# EVENT register map
Vendor: Texas Instruments
Registers are 32-bit, read-only, reset 0x0 unless marked. A register's access mark holds for its fields unless they carry their own. Offsets are as the file gives them; [hi:lo] are bit positions; {n}, {i} and the like mark numbered series; 'fields as' and 'values as' point back to an identical list.

## EVENT — Event Fabric Component Definition
0x00 CPUIRQSEL0 reset 0x4 — Output Selection for CPU Interrupt 0
  [6:0] EV — Read only selection value
    4=AON_GPIO_EDGE (Edge detect event from IOC. Configureded by the IOC:IOCFGn.EDGE_IRQ_EN and IOC:IOCFGn.EDGE_DET settings)
0x04 CPUIRQSEL1 reset 0x9 — Output Selection for CPU Interrupt 1
  [6:0] EV — Read only selection value
    9=I2C_IRQ (Interrupt event from I2C)
0x08 CPUIRQSEL2 reset 0x1E — Output Selection for CPU Interrupt 2
  [6:0] EV — Read only selection value
    30=RFC_CPE_1 (Combined Interrupt for CPE Generated events. Corresponding flags are here RFC_DBELL:RFCPEIFG. Only interrupts selected with CPE1 in RFC_DBELL:RFCPEIFG can trigger a RFC_CPE_1 event)
0x0C CPUIRQSEL3 reset 0x38 — Output Selection for CPU Interrupt 3
0x10 CPUIRQSEL4 reset 0x7 — Output Selection for CPU Interrupt 4
  [6:0] EV — Read only selection value
    7=AON_RTC_COMB (Event from AON_RTC, controlled by the AON_RTC:CTL.COMB_EV_MASK setting)
0x14 CPUIRQSEL5 reset 0x24 — Output Selection for CPU Interrupt 5
  [6:0] EV — Read only selection value
    36=UART0_COMB (UART0 combined interrupt, interrupt flags are found here UART0:MIS)
0x18 CPUIRQSEL6 reset 0x1C — Output Selection for CPU Interrupt 6
  [6:0] EV — Read only selection value
    28=AUX_SWEV0 (AUX software event 0, triggered by AUX_EVCTL:SWEVSET.SWEV0, also available as AUX_EVENT0 AON wake up event. MCU domain wakeup control AON_EVENT:MCUWUSEL AUX domain wakeup control AON_EVENT:AUXWUSEL)
0x1C CPUIRQSEL7 reset 0x22 — Output Selection for CPU Interrupt 7
  [6:0] EV — Read only selection value
    34=SSI0_COMB (SSI0 combined interrupt, interrupt flags are found here SSI0:MIS)
0x20 CPUIRQSEL8 reset 0x23 — Output Selection for CPU Interrupt 8
  [6:0] EV — Read only selection value
    35=SSI1_COMB (SSI1 combined interrupt, interrupt flags are found here SSI1:MIS)
0x24 CPUIRQSEL9 reset 0x1B — Output Selection for CPU Interrupt 9
  [6:0] EV — Read only selection value
    27=RFC_CPE_0 (Combined Interrupt for CPE Generated events. Corresponding flags are here RFC_DBELL:RFCPEIFG. Only interrupts selected with CPE0 in RFC_DBELL:RFCPEIFG can trigger a RFC_CPE_0 event)
0x28 CPUIRQSEL10 reset 0x1A — Output Selection for CPU Interrupt 10
  [6:0] EV — Read only selection value
    26=RFC_HW_COMB (Combined RFC hardware interrupt, corresponding flag is here RFC_DBELL:RFHWIFG)
0x2C CPUIRQSEL11 reset 0x19 — Output Selection for CPU Interrupt 11
  [6:0] EV — Read only selection value
    25=RFC_CMD_ACK (RFC Doorbell Command Acknowledgement Interrupt, equvialent to RFC_DBELL:RFACKIFG.ACKFLAG)
0x30 CPUIRQSEL12 reset 0x8 — Output Selection for CPU Interrupt 12
  [6:0] EV — Read only selection value
    8=I2S_IRQ (Interrupt event from I2S)
0x34 CPUIRQSEL13 reset 0x1D — Output Selection for CPU Interrupt 13
  [6:0] EV — Read only selection value
    29=AUX_SWEV1 (AUX software event 1, triggered by AUX_EVCTL:SWEVSET.SWEV1, also available as AUX_EVENT2 AON wake up event. MCU domain wakeup control AON_EVENT:MCUWUSEL AUX domain wakeup control AON_EVENT:AUXWUSEL)
0x38 CPUIRQSEL14 reset 0x18 — Output Selection for CPU Interrupt 14
  [6:0] EV — Read only selection value
    24=WDT_IRQ (Watchdog interrupt event, controlled by WDT:CTL.INTEN)
0x3C CPUIRQSEL15 reset 0x10 — Output Selection for CPU Interrupt 15
  [6:0] EV — Read only selection value
    16=GPT0A (GPT0A interrupt event, controlled by GPT0:TAMR)
0x40 CPUIRQSEL16 reset 0x11 — Output Selection for CPU Interrupt 16
  [6:0] EV — Read only selection value
    17=GPT0B (GPT0B interrupt event, controlled by GPT0:TBMR)
0x44 CPUIRQSEL17 reset 0x12 — Output Selection for CPU Interrupt 17
  [6:0] EV — Read only selection value
    18=GPT1A (GPT1A interrupt event, controlled by GPT1:TAMR)
0x48 CPUIRQSEL18 reset 0x13 — Output Selection for CPU Interrupt 18
  [6:0] EV — Read only selection value
    19=GPT1B (GPT1B interrupt event, controlled by GPT1:TBMR)
0x4C CPUIRQSEL19 reset 0xC — Output Selection for CPU Interrupt 19
  [6:0] EV — Read only selection value
    12=GPT2A (GPT2A interrupt event, controlled by GPT2:TAMR)
0x50 CPUIRQSEL20 reset 0xD — Output Selection for CPU Interrupt 20
  [6:0] EV — Read only selection value
    13=GPT2B (GPT2B interrupt event, controlled by GPT2:TBMR)
0x54 CPUIRQSEL21 reset 0xE — Output Selection for CPU Interrupt 21
  [6:0] EV — Read only selection value
    14=GPT3A (GPT3A interrupt event, controlled by GPT3:TAMR)
0x58 CPUIRQSEL22 reset 0xF — Output Selection for CPU Interrupt 22
  [6:0] EV — Read only selection value
    15=GPT3B (GPT3B interrupt event, controlled by GPT3:TBMR)
0x5C CPUIRQSEL23 reset 0x5D — Output Selection for CPU Interrupt 23
  [6:0] EV — Read only selection value
    93=CRYPTO_RESULT_AVAIL_IRQ (CRYPTO result available interupt event, the corresponding flag is found here CRYPTO:IRQSTAT.RESULT_AVAIL. Controlled by CRYPTO:IRQSTAT.RESULT_AVAIL)
0x60 CPUIRQSEL24 reset 0x27 — Output Selection for CPU Interrupt 24
  [6:0] EV — Read only selection value
    39=DMA_DONE_COMB (Combined DMA done, corresponding flags are here UDMA0:REQDONE)
0x64 CPUIRQSEL25 reset 0x26 — Output Selection for CPU Interrupt 25
  [6:0] EV — Read only selection value
    38=DMA_ERR (DMA bus error, corresponds to UDMA0:ERROR.STATUS)
0x68 CPUIRQSEL26 reset 0x15 — Output Selection for CPU Interrupt 26
  [6:0] EV — Read only selection value
    21=FLASH (FLASH controller error event, the status flags are FLASH:FEDACSTAT.FSM_DONE and FLASH:FEDACSTAT.RVF_INT)
0x6C CPUIRQSEL27 reset 0x64 — Output Selection for CPU Interrupt 27
  [6:0] EV — Read only selection value
    100=SWEV0 (Software event 0, triggered by SWEV.SWEV0)
0x70 CPUIRQSEL28 reset 0xB — Output Selection for CPU Interrupt 28
  [6:0] EV — Read only selection value
    11=AUX_COMB (AUX combined event, the corresponding flag register is here AUX_EVCTL:EVTOMCUFLAGS)
0x74 CPUIRQSEL29 reset 0x1 — Output Selection for CPU Interrupt 29
  [6:0] EV — Read only selection value
    1=AON_PROG0 (AON programmable event 0. Event selected by AON_EVENT MCU event selector, AON_EVENT:EVTOMCUSEL.AON_PROG0_EV)
0x78 CPUIRQSEL30 access per field — Output Selection for CPU Interrupt 30
  [6:0] EV rw — Read/write selection value Writing any other value than values defined by a ENUM may result in undefined behavior.
    121=ALWAYS_ACTIVE (Always asserted); 119=AON_RTC_UPD (RTC periodic event controlled by AON_RTC:CTL.RTC_UPD_EN); 114=AUX_OBSMUX0 (Loopback of OBSMUX0 through AUX, corresponds to AUX_EVCTL:EVTOMCUFLAGS.OBSMUX0); 113=AUX_ADC_FIFO_ALMOST_FULL (AUX ADC FIFO watermark event, corresponds to AUX_EVCTL:EVTOMCUFLAGS.ADC_FIFO_ALMOST_FULL); 112=AUX_ADC_DONE (AUX ADC done, corresponds to AUX_EVCTL:EVTOMCUFLAGS.ADC_DONE); 111=AUX_SMPH_AUTOTAKE_DONE (Autotake event from AUX semaphore, configured by AUX_SMPH:AUTOTAKE); 110=AUX_TIMER1_EV (AUX timer 1 event, corresponds to AUX_EVCTL:EVTOMCUFLAGS.TIMER1_EV); 109=AUX_TIMER0_EV (AUX timer 0 event, corresponds to AUX_EVCTL:EVTOMCUFLAGS.TIMER0_EV); 108=AUX_TDC_DONE (AUX TDC measurement done event, corresponds to the flag AUX_EVCTL:EVTOMCUFLAGS.TDC_DONE and the AUX_TDC status AUX_TDC:STAT.DONE); 107=AUX_COMPB (AUX Compare B event, corresponds to AUX_EVCTL:EVTOMCUFLAGS.AUX_COMPB); 105=AUX_AON_WU_EV (AON wakeup event, corresponds flags are here AUX_EVCTL:EVTOMCUFLAGS.AON_WU_EV); 94=CRYPTO_DMA_DONE_IRQ (CRYPTO DMA input done event, the correspondingg flag is CRYPTO:IRQSTAT.DMA_IN_DONE. Controlled by CRYPTO:IRQEN.DMA_IN_DONE); 22=DMA_CH18_DONE (DMA done for software tiggered UDMA channel 18, see UDMA0:SOFTREQ); 20=DMA_CH0_DONE (DMA done for software tiggered UDMA channel 0, see UDMA0:SOFTREQ); 10=AON_AUX_SWEV0 (AUX Software event 0, AUX_EVCTL:SWEVSET.SWEV0); 8=I2S_IRQ (Interrupt event from I2S); 3=AON_PROG2 (AON programmable event 2. Event selected by AON_EVENT MCU event selector, AON_EVENT:EVTOMCUSEL.AON_PROG2_EV); 2=AON_PROG1 (AON programmable event 1. Event selected by AON_EVENT MCU event selector, AON_EVENT:EVTOMCUSEL.AON_PROG1_EV); 0=NONE (Always inactive)
0x7C CPUIRQSEL31 reset 0x6A — Output Selection for CPU Interrupt 31
  [6:0] EV — Read only selection value
    106=AUX_COMPA (AUX Compare A event, corresponds to AUX_EVCTL:EVTOMCUFLAGS.AUX_COMPA)
0x80 CPUIRQSEL32 reset 0x73 — Output Selection for CPU Interrupt 32
  [6:0] EV — Read only selection value
    115=AUX_ADC_IRQ (AUX ADC interrupt event, corresponds to AUX_EVCTL:EVTOMCUFLAGS.ADC_IRQ. Status flags are found here AUX_EVCTL:EVTOMCUFLAGS)
0x84 CPUIRQSEL33 reset 0x68 — Output Selection for CPU Interrupt 33
  [6:0] EV — Read only selection value
    104=TRNG_IRQ (TRNG Interrupt event, controlled by TRNG:IRQEN.EN)
0x100 RFCSEL0 reset 0x3D — Output Selection for RFC Event 0
  [6:0] EV — Read only selection value
    61=GPT0A_CMP (GPT0A compare event. Configured by GPT0:TAMR.TCACT)
0x104 RFCSEL1 reset 0x3E — Output Selection for RFC Event 1
  [6:0] EV — Read only selection value
    62=GPT0B_CMP (GPT0B compare event. Configured by GPT0:TBMR.TCACT)
0x108 RFCSEL2 reset 0x3F — Output Selection for RFC Event 2
  [6:0] EV — Read only selection value
    63=GPT1A_CMP (GPT1A compare event. Configured by GPT1:TAMR.TCACT)
0x10C RFCSEL3 reset 0x40 — Output Selection for RFC Event 3
  [6:0] EV — Read only selection value
    64=GPT1B_CMP (GPT1B compare event. Configured by GPT1:TBMR.TCACT)
0x110 RFCSEL4 reset 0x41 — Output Selection for RFC Event 4
  [6:0] EV — Read only selection value
    65=GPT2A_CMP (GPT2A compare event. Configured by GPT2:TAMR.TCACT)
0x114 RFCSEL5 reset 0x42 — Output Selection for RFC Event 5
  [6:0] EV — Read only selection value
    66=GPT2B_CMP (GPT2B compare event. Configured by GPT2:TBMR.TCACT)
0x118 RFCSEL6 reset 0x43 — Output Selection for RFC Event 6
  [6:0] EV — Read only selection value
    67=GPT3A_CMP (GPT3A compare event. Configured by GPT3:TAMR.TCACT)
0x11C RFCSEL7 reset 0x44 — Output Selection for RFC Event 7
  [6:0] EV — Read only selection value
    68=GPT3B_CMP (GPT3B compare event. Configured by GPT3:TBMR.TCACT)
0x120 RFCSEL8 reset 0x77 — Output Selection for RFC Event 8
  [6:0] EV — Read only selection value
    119=AON_RTC_UPD (RTC periodic event controlled by AON_RTC:CTL.RTC_UPD_EN)
0x124 RFCSEL9 access per field reset 0x2 — Output Selection for RFC Event 9
  [6:0] EV rw — Read/write selection value Writing any other value than values defined by a ENUM may result in undefined behavior.
    121=ALWAYS_ACTIVE (Always asserted); 115=AUX_ADC_IRQ (AUX ADC interrupt event, corresponds to AUX_EVCTL:EVTOMCUFLAGS.ADC_IRQ. Status flags are found here AUX_EVCTL:EVTOMCUFLAGS); 114=AUX_OBSMUX0 (Loopback of OBSMUX0 through AUX, corresponds to AUX_EVCTL:EVTOMCUFLAGS.OBSMUX0); 113=AUX_ADC_FIFO_ALMOST_FULL (AUX ADC FIFO watermark event, corresponds to AUX_EVCTL:EVTOMCUFLAGS.ADC_FIFO_ALMOST_FULL); 112=AUX_ADC_DONE (AUX ADC done, corresponds to AUX_EVCTL:EVTOMCUFLAGS.ADC_DONE); 111=AUX_SMPH_AUTOTAKE_DONE (Autotake event from AUX semaphore, configured by AUX_SMPH:AUTOTAKE); 110=AUX_TIMER1_EV (AUX timer 1 event, corresponds to AUX_EVCTL:EVTOMCUFLAGS.TIMER1_EV); 109=AUX_TIMER0_EV (AUX timer 0 event, corresponds to AUX_EVCTL:EVTOMCUFLAGS.TIMER0_EV); 108=AUX_TDC_DONE (AUX TDC measurement done event, corresponds to the flag AUX_EVCTL:EVTOMCUFLAGS.TDC_DONE and the AUX_TDC status AUX_TDC:STAT.DONE); 107=AUX_COMPB (AUX Compare B event, corresponds to AUX_EVCTL:EVTOMCUFLAGS.AUX_COMPB); 106=AUX_COMPA (AUX Compare A event, corresponds to AUX_EVCTL:EVTOMCUFLAGS.AUX_COMPA); 105=AUX_AON_WU_EV (AON wakeup event, corresponds flags are here AUX_EVCTL:EVTOMCUFLAGS.AON_WU_EV); 101=SWEV1 (Software event 1, triggered by SWEV.SWEV1); 100=SWEV0 (Software event 0, triggered by SWEV.SWEV0); 93=CRYPTO_RESULT_AVAIL_IRQ (CRYPTO result available interupt event, the corresponding flag is found here CRYPTO:IRQSTAT.RESULT_AVAIL. Controlled by CRYPTO:IRQSTAT.RESULT_AVAIL); 39=DMA_DONE_COMB (Combined DMA done, corresponding flags are here UDMA0:REQDONE); 36=UART0_COMB (UART0 combined interrupt, interrupt flags are found here UART0:MIS); 35=SSI1_COMB (SSI1 combined interrupt, interrupt flags are found here SSI1:MIS); 34=SSI0_COMB (SSI0 combined interrupt, interrupt flags are found here SSI0:MIS); 24=WDT_IRQ (Watchdog interrupt event, controlled by WDT:CTL.INTEN); 10=AON_AUX_SWEV0 (AUX Software event 0, AUX_EVCTL:SWEVSET.SWEV0); 8=I2S_IRQ (Interrupt event from I2S); 2=AON_PROG1 (AON programmable event 1. Event selected by AON_EVENT MCU event selector, AON_EVENT:EVTOMCUSEL.AON_PROG1_EV); 1=AON_PROG0 (AON programmable event 0. Event selected by AON_EVENT MCU event selector, AON_EVENT:EVTOMCUSEL.AON_PROG0_EV); 0=NONE (Always inactive)
0x200 GPT0ACAPTSEL access per field reset 0x55 — Output Selection for GPT0 0
  [6:0] EV rw — Read/write selection value Writing any other value than values defined by a ENUM may result in undefined behavior.
    121=ALWAYS_ACTIVE (Always asserted); 119=AON_RTC_UPD (RTC periodic event controlled by AON_RTC:CTL.RTC_UPD_EN); 115=AUX_ADC_IRQ (AUX ADC interrupt event, corresponds to AUX_EVCTL:EVTOMCUFLAGS.ADC_IRQ. Status flags are found here AUX_EVCTL:EVTOMCUFLAGS); 114=AUX_OBSMUX0 (Loopback of OBSMUX0 through AUX, corresponds to AUX_EVCTL:EVTOMCUFLAGS.OBSMUX0); 113=AUX_ADC_FIFO_ALMOST_FULL (AUX ADC FIFO watermark event, corresponds to AUX_EVCTL:EVTOMCUFLAGS.ADC_FIFO_ALMOST_FULL); 112=AUX_ADC_DONE (AUX ADC done, corresponds to AUX_EVCTL:EVTOMCUFLAGS.ADC_DONE); 111=AUX_SMPH_AUTOTAKE_DONE (Autotake event from AUX semaphore, configured by AUX_SMPH:AUTOTAKE); 110=AUX_TIMER1_EV (AUX timer 1 event, corresponds to AUX_EVCTL:EVTOMCUFLAGS.TIMER1_EV); 109=AUX_TIMER0_EV (AUX timer 0 event, corresponds to AUX_EVCTL:EVTOMCUFLAGS.TIMER0_EV); 108=AUX_TDC_DONE (AUX TDC measurement done event, corresponds to the flag AUX_EVCTL:EVTOMCUFLAGS.TDC_DONE and the AUX_TDC status AUX_TDC:STAT.DONE); 107=AUX_COMPB (AUX Compare B event, corresponds to AUX_EVCTL:EVTOMCUFLAGS.AUX_COMPB); 106=AUX_COMPA (AUX Compare A event, corresponds to AUX_EVCTL:EVTOMCUFLAGS.AUX_COMPA); 105=AUX_AON_WU_EV (AON wakeup event, corresponds flags are here AUX_EVCTL:EVTOMCUFLAGS.AON_WU_EV); 86=PORT_EVENT1 (Port capture event from IOC, configured by IOC:IOCFGn.PORT_ID. Events on ports configured with ENUM PORT_EVENT1 wil be routed here.); 85=PORT_EVENT0 (Port capture event from IOC, configured by IOC:IOCFGn.PORT_ID. Events on ports configured with ENUM PORT_EVENT0 wil be routed here.); 68=GPT3B_CMP (GPT3B compare event. Configured by GPT3:TBMR.TCACT); 67=GPT3A_CMP (GPT3A compare event. Configured by GPT3:TAMR.TCACT); 66=GPT2B_CMP (GPT2B compare event. Configured by GPT2:TBMR.TCACT); 65=GPT2A_CMP (GPT2A compare event. Configured by GPT2:TAMR.TCACT); 64=GPT1B_CMP (GPT1B compare event. Configured by GPT1:TBMR.TCACT); 63=GPT1A_CMP (GPT1A compare event. Configured by GPT1:TAMR.TCACT); 62=GPT0B_CMP (GPT0B compare event. Configured by GPT0:TBMR.TCACT); 61=GPT0A_CMP (GPT0A compare event. Configured by GPT0:TAMR.TCACT); 36=UART0_COMB (UART0 combined interrupt, interrupt flags are found here UART0:MIS); 35=SSI1_COMB (SSI1 combined interrupt, interrupt flags are found here SSI1:MIS); 34=SSI0_COMB (SSI0 combined interrupt, interrupt flags are found here SSI0:MIS); 30=RFC_CPE_1 (Combined Interrupt for CPE Generated events. Corresponding flags are here RFC_DBELL:RFCPEIFG. Only interrupts selected with CPE1 in RFC_DBELL:RFCPEIFG can trigger a RFC_CPE_1 event); 27=RFC_CPE_0 (Combined Interrupt for CPE Generated events. Corresponding flags are here RFC_DBELL:RFCPEIFG. Only interrupts selected with CPE0 in RFC_DBELL:RFCPEIFG can trigger a RFC_CPE_0 event); 26=RFC_HW_COMB (Combined RFC hardware interrupt, corresponding flag is here RFC_DBELL:RFHWIFG); 25=RFC_CMD_ACK (RFC Doorbell Command Acknowledgement Interrupt, equvialent to RFC_DBELL:RFACKIFG.ACKFLAG); 21=FLASH (FLASH controller error event, the status flags are FLASH:FEDACSTAT.FSM_DONE and FLASH:FEDACSTAT.RVF_INT); 11=AUX_COMB (AUX combined event, the corresponding flag register is here AUX_EVCTL:EVTOMCUFLAGS); 9=I2C_IRQ (Interrupt event from I2C); 7=AON_RTC_COMB (Event from AON_RTC, controlled by the AON_RTC:CTL.COMB_EV_MASK setting); 4=AON_GPIO_EDGE (Edge detect event from IOC. Configureded by the IOC:IOCFGn.EDGE_IRQ_EN and IOC:IOCFGn.EDGE_DET settings); 0=NONE (Always inactive)
0x204 GPT0BCAPTSEL access per field reset 0x56 — Output Selection for GPT0 1
  fields as GPT0ACAPTSEL
0x300 GPT1ACAPTSEL access per field reset 0x57 — Output Selection for GPT1 0
  [6:0] EV rw — Read/write selection value Writing any other value than values defined by a ENUM may result in undefined behavior.
    121=ALWAYS_ACTIVE (Always asserted); 119=AON_RTC_UPD (RTC periodic event controlled by AON_RTC:CTL.RTC_UPD_EN); 115=AUX_ADC_IRQ (AUX ADC interrupt event, corresponds to AUX_EVCTL:EVTOMCUFLAGS.ADC_IRQ. Status flags are found here AUX_EVCTL:EVTOMCUFLAGS); 114=AUX_OBSMUX0 (Loopback of OBSMUX0 through AUX, corresponds to AUX_EVCTL:EVTOMCUFLAGS.OBSMUX0); 113=AUX_ADC_FIFO_ALMOST_FULL (AUX ADC FIFO watermark event, corresponds to AUX_EVCTL:EVTOMCUFLAGS.ADC_FIFO_ALMOST_FULL); 112=AUX_ADC_DONE (AUX ADC done, corresponds to AUX_EVCTL:EVTOMCUFLAGS.ADC_DONE); 111=AUX_SMPH_AUTOTAKE_DONE (Autotake event from AUX semaphore, configured by AUX_SMPH:AUTOTAKE); 110=AUX_TIMER1_EV (AUX timer 1 event, corresponds to AUX_EVCTL:EVTOMCUFLAGS.TIMER1_EV); 109=AUX_TIMER0_EV (AUX timer 0 event, corresponds to AUX_EVCTL:EVTOMCUFLAGS.TIMER0_EV); 108=AUX_TDC_DONE (AUX TDC measurement done event, corresponds to the flag AUX_EVCTL:EVTOMCUFLAGS.TDC_DONE and the AUX_TDC status AUX_TDC:STAT.DONE); 107=AUX_COMPB (AUX Compare B event, corresponds to AUX_EVCTL:EVTOMCUFLAGS.AUX_COMPB); 106=AUX_COMPA (AUX Compare A event, corresponds to AUX_EVCTL:EVTOMCUFLAGS.AUX_COMPA); 105=AUX_AON_WU_EV (AON wakeup event, corresponds flags are here AUX_EVCTL:EVTOMCUFLAGS.AON_WU_EV); 88=PORT_EVENT3 (Port capture event from IOC, configured by IOC:IOCFGn.PORT_ID. Events on ports configured with ENUM PORT_EVENT3 wil be routed here.); 87=PORT_EVENT2 (Port capture event from IOC, configured by IOC:IOCFGn.PORT_ID. Events on ports configured with ENUM PORT_EVENT2 wil be routed here.); 68=GPT3B_CMP (GPT3B compare event. Configured by GPT3:TBMR.TCACT); 67=GPT3A_CMP (GPT3A compare event. Configured by GPT3:TAMR.TCACT); 66=GPT2B_CMP (GPT2B compare event. Configured by GPT2:TBMR.TCACT); 65=GPT2A_CMP (GPT2A compare event. Configured by GPT2:TAMR.TCACT); 64=GPT1B_CMP (GPT1B compare event. Configured by GPT1:TBMR.TCACT); 63=GPT1A_CMP (GPT1A compare event. Configured by GPT1:TAMR.TCACT); 62=GPT0B_CMP (GPT0B compare event. Configured by GPT0:TBMR.TCACT); 61=GPT0A_CMP (GPT0A compare event. Configured by GPT0:TAMR.TCACT); 36=UART0_COMB (UART0 combined interrupt, interrupt flags are found here UART0:MIS); 35=SSI1_COMB (SSI1 combined interrupt, interrupt flags are found here SSI1:MIS); 34=SSI0_COMB (SSI0 combined interrupt, interrupt flags are found here SSI0:MIS); 30=RFC_CPE_1 (Combined Interrupt for CPE Generated events. Corresponding flags are here RFC_DBELL:RFCPEIFG. Only interrupts selected with CPE1 in RFC_DBELL:RFCPEIFG can trigger a RFC_CPE_1 event); 27=RFC_CPE_0 (Combined Interrupt for CPE Generated events. Corresponding flags are here RFC_DBELL:RFCPEIFG. Only interrupts selected with CPE0 in RFC_DBELL:RFCPEIFG can trigger a RFC_CPE_0 event); 26=RFC_HW_COMB (Combined RFC hardware interrupt, corresponding flag is here RFC_DBELL:RFHWIFG); 25=RFC_CMD_ACK (RFC Doorbell Command Acknowledgement Interrupt, equvialent to RFC_DBELL:RFACKIFG.ACKFLAG); 21=FLASH (FLASH controller error event, the status flags are FLASH:FEDACSTAT.FSM_DONE and FLASH:FEDACSTAT.RVF_INT); 11=AUX_COMB (AUX combined event, the corresponding flag register is here AUX_EVCTL:EVTOMCUFLAGS); 9=I2C_IRQ (Interrupt event from I2C); 7=AON_RTC_COMB (Event from AON_RTC, controlled by the AON_RTC:CTL.COMB_EV_MASK setting); 4=AON_GPIO_EDGE (Edge detect event from IOC. Configureded by the IOC:IOCFGn.EDGE_IRQ_EN and IOC:IOCFGn.EDGE_DET settings); 0=NONE (Always inactive)
0x304 GPT1BCAPTSEL access per field reset 0x58 — Output Selection for GPT1 1
  fields as GPT1ACAPTSEL
0x400 GPT2ACAPTSEL access per field reset 0x59 — Output Selection for GPT2 0
  [6:0] EV rw — Read/write selection value Writing any other value than values defined by a ENUM may result in undefined behavior.
    121=ALWAYS_ACTIVE (Always asserted); 119=AON_RTC_UPD (RTC periodic event controlled by AON_RTC:CTL.RTC_UPD_EN); 115=AUX_ADC_IRQ (AUX ADC interrupt event, corresponds to AUX_EVCTL:EVTOMCUFLAGS.ADC_IRQ. Status flags are found here AUX_EVCTL:EVTOMCUFLAGS); 114=AUX_OBSMUX0 (Loopback of OBSMUX0 through AUX, corresponds to AUX_EVCTL:EVTOMCUFLAGS.OBSMUX0); 113=AUX_ADC_FIFO_ALMOST_FULL (AUX ADC FIFO watermark event, corresponds to AUX_EVCTL:EVTOMCUFLAGS.ADC_FIFO_ALMOST_FULL); 112=AUX_ADC_DONE (AUX ADC done, corresponds to AUX_EVCTL:EVTOMCUFLAGS.ADC_DONE); 111=AUX_SMPH_AUTOTAKE_DONE (Autotake event from AUX semaphore, configured by AUX_SMPH:AUTOTAKE); 110=AUX_TIMER1_EV (AUX timer 1 event, corresponds to AUX_EVCTL:EVTOMCUFLAGS.TIMER1_EV); 109=AUX_TIMER0_EV (AUX timer 0 event, corresponds to AUX_EVCTL:EVTOMCUFLAGS.TIMER0_EV); 108=AUX_TDC_DONE (AUX TDC measurement done event, corresponds to the flag AUX_EVCTL:EVTOMCUFLAGS.TDC_DONE and the AUX_TDC status AUX_TDC:STAT.DONE); 107=AUX_COMPB (AUX Compare B event, corresponds to AUX_EVCTL:EVTOMCUFLAGS.AUX_COMPB); 106=AUX_COMPA (AUX Compare A event, corresponds to AUX_EVCTL:EVTOMCUFLAGS.AUX_COMPA); 105=AUX_AON_WU_EV (AON wakeup event, corresponds flags are here AUX_EVCTL:EVTOMCUFLAGS.AON_WU_EV); 90=PORT_EVENT5 (Port capture event from IOC, configured by IOC:IOCFGn.PORT_ID. Events on ports configured with ENUM PORT_EVENT4 wil be routed here.); 89=PORT_EVENT4 (Port capture event from IOC, configured by IOC:IOCFGn.PORT_ID. Events on ports configured with ENUM PORT_EVENT4 wil be routed here.); 68=GPT3B_CMP (GPT3B compare event. Configured by GPT3:TBMR.TCACT); 67=GPT3A_CMP (GPT3A compare event. Configured by GPT3:TAMR.TCACT); 66=GPT2B_CMP (GPT2B compare event. Configured by GPT2:TBMR.TCACT); 65=GPT2A_CMP (GPT2A compare event. Configured by GPT2:TAMR.TCACT); 64=GPT1B_CMP (GPT1B compare event. Configured by GPT1:TBMR.TCACT); 63=GPT1A_CMP (GPT1A compare event. Configured by GPT1:TAMR.TCACT); 62=GPT0B_CMP (GPT0B compare event. Configured by GPT0:TBMR.TCACT); 61=GPT0A_CMP (GPT0A compare event. Configured by GPT0:TAMR.TCACT); 36=UART0_COMB (UART0 combined interrupt, interrupt flags are found here UART0:MIS); 35=SSI1_COMB (SSI1 combined interrupt, interrupt flags are found here SSI1:MIS); 34=SSI0_COMB (SSI0 combined interrupt, interrupt flags are found here SSI0:MIS); 30=RFC_CPE_1 (Combined Interrupt for CPE Generated events. Corresponding flags are here RFC_DBELL:RFCPEIFG. Only interrupts selected with CPE1 in RFC_DBELL:RFCPEIFG can trigger a RFC_CPE_1 event); 27=RFC_CPE_0 (Combined Interrupt for CPE Generated events. Corresponding flags are here RFC_DBELL:RFCPEIFG. Only interrupts selected with CPE0 in RFC_DBELL:RFCPEIFG can trigger a RFC_CPE_0 event); 26=RFC_HW_COMB (Combined RFC hardware interrupt, corresponding flag is here RFC_DBELL:RFHWIFG); 25=RFC_CMD_ACK (RFC Doorbell Command Acknowledgement Interrupt, equvialent to RFC_DBELL:RFACKIFG.ACKFLAG); 21=FLASH (FLASH controller error event, the status flags are FLASH:FEDACSTAT.FSM_DONE and FLASH:FEDACSTAT.RVF_INT); 11=AUX_COMB (AUX combined event, the corresponding flag register is here AUX_EVCTL:EVTOMCUFLAGS); 9=I2C_IRQ (Interrupt event from I2C); 7=AON_RTC_COMB (Event from AON_RTC, controlled by the AON_RTC:CTL.COMB_EV_MASK setting); 4=AON_GPIO_EDGE (Edge detect event from IOC. Configureded by the IOC:IOCFGn.EDGE_IRQ_EN and IOC:IOCFGn.EDGE_DET settings); 0=NONE (Always inactive)
0x404 GPT2BCAPTSEL access per field reset 0x5A — Output Selection for GPT2 1
  fields as GPT2ACAPTSEL
0x500 UDMACH0SSEL — Software should not rely on the value of a reserved. Writing any other value than the reset value may result in undefined behavior.
  [31:0] EV
    0=NONE (Always inactive)
0x504 UDMACH0BSEL — Software should not rely on the value of a reserved. Writing any other value than the reset value may result in undefined behavior.
  [31:0] EV
    0=NONE (Always inactive)
0x508 UDMACH1SSEL reset 0x31 — Output Selection for DMA Channel 1 SREQ
  [6:0] EV — Read only selection value
    49=UART0_RX_DMASREQ (UART0 RX DMA single request, controlled by UART0:DMACTL.RXDMAE)
0x50C UDMACH1BSEL reset 0x30 — Output Selection for DMA Channel 1 REQ
  [6:0] EV — Read only selection value
    48=UART0_RX_DMABREQ (UART0 RX DMA burst request, controlled by UART0:DMACTL.RXDMAE)
0x510 UDMACH2SSEL reset 0x33 — Output Selection for DMA Channel 2 SREQ
  [6:0] EV — Read only selection value
    51=UART0_TX_DMASREQ (UART0 TX DMA single request, controlled by UART0:DMACTL.TXDMAE)
0x514 UDMACH2BSEL reset 0x32 — Output Selection for DMA Channel 2 REQ
  [6:0] EV — Read only selection value
    50=UART0_TX_DMABREQ (UART0 TX DMA burst request, controlled by UART0:DMACTL.TXDMAE)
0x518 UDMACH3SSEL reset 0x29 — Output Selection for DMA Channel 3 SREQ
  [6:0] EV — Read only selection value
    41=SSI0_RX_DMASREQ (SSI0 RX DMA single request, controlled by SSI0:DMACR.RXDMAE)
0x51C UDMACH3BSEL reset 0x28 — Output Selection for DMA Channel 3 REQ
  [6:0] EV — Read only selection value
    40=SSI0_RX_DMABREQ (SSI0 RX DMA burst request , controlled by SSI0:DMACR.RXDMAE)
0x520 UDMACH4SSEL reset 0x2B — Output Selection for DMA Channel 4 SREQ
  [6:0] EV — Read only selection value
    43=SSI0_TX_DMASREQ (SSI0 TX DMA single request, controlled by SSI0:DMACR.TXDMAE)
0x524 UDMACH4BSEL reset 0x2A — Output Selection for DMA Channel 4 REQ
  [6:0] EV — Read only selection value
    42=SSI0_TX_DMABREQ (SSI0 TX DMA burst request , controlled by SSI0:DMACR.TXDMAE)
0x528 UDMACH5SSEL reset 0x3A — Output Selection for DMA Channel 5 SREQ
0x52C UDMACH5BSEL reset 0x39 — Output Selection for DMA Channel 5 REQ
0x530 UDMACH6SSEL reset 0x3C — Output Selection for DMA Channel 6 SREQ
0x534 UDMACH6BSEL reset 0x3B — Output Selection for DMA Channel 6 REQ
0x538 UDMACH7SSEL reset 0x75 — Output Selection for DMA Channel 7 SREQ
  [6:0] EV — Read only selection value
    117=AUX_DMASREQ (DMA single request event from AUX, configured by AUX_EVCTL:DMACTL)
0x53C UDMACH7BSEL reset 0x76 — Output Selection for DMA Channel 7 REQ
  [6:0] EV — Read only selection value
    118=AUX_DMABREQ (DMA burst request event from AUX, configured by AUX_EVCTL:DMACTL)
0x540 UDMACH8SSEL reset 0x74 — Output Selection for DMA Channel 8 SREQ Single request is ignored for this channel
  [6:0] EV — Read only selection value
    116=AUX_SW_DMABREQ (DMA sofware trigger from AUX, triggered by AUX_EVCTL:DMASWREQ.START)
0x544 UDMACH8BSEL reset 0x74 — Output Selection for DMA Channel 8 REQ
  fields as UDMACH8SSEL
0x548 UDMACH9SSEL access per field reset 0x45 — Output Selection for DMA Channel 9 SREQ DMA_DONE for the corresponding DMA channel is available as interrupt on GPT0 as GPT0:RIS.DMAARIS
  [6:0] EV rw — Read/write selection value Writing any other value than values defined by a ENUM may result in undefined behavior.
    121=ALWAYS_ACTIVE (Always asserted); 84=GPT3B_DMABREQ (GPT3B DMA trigger event. Configured by GPT3:DMAEV); 83=GPT3A_DMABREQ (GPT3A DMA trigger event. Configured by GPT3:DMAEV); 82=GPT2B_DMABREQ (GPT2B DMA trigger event. Configured by GPT2:DMAEV); 81=GPT2A_DMABREQ (GPT2A DMA trigger event. Configured by GPT2:DMAEV); 80=GPT1B_DMABREQ (GPT1B DMA trigger event. Configured by GPT1:DMAEV); 79=GPT1A_DMABREQ (GPT1A DMA trigger event. Configured by GPT1:DMAEV); 78=GPT0B_DMABREQ (GPT0B DMA trigger event. Configured by GPT0:DMAEV); 77=GPT0A_DMABREQ (GPT0A DMA trigger event. Configured by GPT0:DMAEV); 69=TIE_LOW (Not used tied to 0); 0=NONE (Always inactive)
0x54C UDMACH9BSEL access per field reset 0x4D — Output Selection for DMA Channel 9 REQ DMA_DONE for the corresponding DMA channel is available as interrupt on GPT0 as GPT0:RIS.DMAARIS
  [6:0] EV rw — Read/write selection value Writing any other value than values defined by a ENUM may result in undefined behavior.
    121=ALWAYS_ACTIVE (Always asserted); 84=GPT3B_DMABREQ (GPT3B DMA trigger event. Configured by GPT3:DMAEV); 83=GPT3A_DMABREQ (GPT3A DMA trigger event. Configured by GPT3:DMAEV); 82=GPT2B_DMABREQ (GPT2B DMA trigger event. Configured by GPT2:DMAEV); 81=GPT2A_DMABREQ (GPT2A DMA trigger event. Configured by GPT2:DMAEV); 80=GPT1B_DMABREQ (GPT1B DMA trigger event. Configured by GPT1:DMAEV); 79=GPT1A_DMABREQ (GPT1A DMA trigger event. Configured by GPT1:DMAEV); 78=GPT0B_DMABREQ (GPT0B DMA trigger event. Configured by GPT0:DMAEV); 77=GPT0A_DMABREQ (GPT0A DMA trigger event. Configured by GPT0:DMAEV); 0=NONE (Always inactive)
0x550 UDMACH10SSEL access per field reset 0x46 — Output Selection for DMA Channel 10 SREQ DMA_DONE for the corresponding DMA channel is available as interrupt on GPT0 as GPT0:RIS.DMABRIS
  [6:0] EV rw — Read/write selection value Writing any other value than values defined by a ENUM may result in undefined behavior.
    121=ALWAYS_ACTIVE (Always asserted); 84=GPT3B_DMABREQ (GPT3B DMA trigger event. Configured by GPT3:DMAEV); 83=GPT3A_DMABREQ (GPT3A DMA trigger event. Configured by GPT3:DMAEV); 82=GPT2B_DMABREQ (GPT2B DMA trigger event. Configured by GPT2:DMAEV); 81=GPT2A_DMABREQ (GPT2A DMA trigger event. Configured by GPT2:DMAEV); 80=GPT1B_DMABREQ (GPT1B DMA trigger event. Configured by GPT1:DMAEV); 79=GPT1A_DMABREQ (GPT1A DMA trigger event. Configured by GPT1:DMAEV); 78=GPT0B_DMABREQ (GPT0B DMA trigger event. Configured by GPT0:DMAEV); 77=GPT0A_DMABREQ (GPT0A DMA trigger event. Configured by GPT0:DMAEV); 70=TIE_LOW (Not used tied to 0); 0=NONE (Always inactive)
0x554 UDMACH10BSEL access per field reset 0x4E — Output Selection for DMA Channel 10 REQ DMA_DONE for the corresponding DMA channel is available as interrupt on GPT0 as GPT0:RIS.DMABRIS
  fields as UDMACH9BSEL
0x558 UDMACH11SSEL access per field reset 0x47 — Output Selection for DMA Channel 11 SREQ DMA_DONE for the corresponding DMA channel is available as interrupt on GPT1 as GPT1:RIS.DMAARIS
  [6:0] EV rw — Read/write selection value Writing any other value than values defined by a ENUM may result in undefined behavior.
    121=ALWAYS_ACTIVE (Always asserted); 84=GPT3B_DMABREQ (GPT3B DMA trigger event. Configured by GPT3:DMAEV); 83=GPT3A_DMABREQ (GPT3A DMA trigger event. Configured by GPT3:DMAEV); 82=GPT2B_DMABREQ (GPT2B DMA trigger event. Configured by GPT2:DMAEV); 81=GPT2A_DMABREQ (GPT2A DMA trigger event. Configured by GPT2:DMAEV); 80=GPT1B_DMABREQ (GPT1B DMA trigger event. Configured by GPT1:DMAEV); 79=GPT1A_DMABREQ (GPT1A DMA trigger event. Configured by GPT1:DMAEV); 78=GPT0B_DMABREQ (GPT0B DMA trigger event. Configured by GPT0:DMAEV); 77=GPT0A_DMABREQ (GPT0A DMA trigger event. Configured by GPT0:DMAEV); 71=TIE_LOW (Not used tied to 0); 0=NONE (Always inactive)
0x55C UDMACH11BSEL access per field reset 0x4F — Output Selection for DMA Channel 11 REQ DMA_DONE for the corresponding DMA channel is available as interrupt on GPT1 as GPT1:RIS.DMAARIS
  fields as UDMACH9BSEL
0x560 UDMACH12SSEL access per field reset 0x48 — Output Selection for DMA Channel 12 SREQ DMA_DONE for the corresponding DMA channel is available as interrupt on GPT1 as GPT1:RIS.DMABRIS
  [6:0] EV rw — Read/write selection value Writing any other value than values defined by a ENUM may result in undefined behavior.
    121=ALWAYS_ACTIVE (Always asserted); 84=GPT3B_DMABREQ (GPT3B DMA trigger event. Configured by GPT3:DMAEV); 83=GPT3A_DMABREQ (GPT3A DMA trigger event. Configured by GPT3:DMAEV); 82=GPT2B_DMABREQ (GPT2B DMA trigger event. Configured by GPT2:DMAEV); 81=GPT2A_DMABREQ (GPT2A DMA trigger event. Configured by GPT2:DMAEV); 80=GPT1B_DMABREQ (GPT1B DMA trigger event. Configured by GPT1:DMAEV); 79=GPT1A_DMABREQ (GPT1A DMA trigger event. Configured by GPT1:DMAEV); 78=GPT0B_DMABREQ (GPT0B DMA trigger event. Configured by GPT0:DMAEV); 77=GPT0A_DMABREQ (GPT0A DMA trigger event. Configured by GPT0:DMAEV); 72=TIE_LOW (Not used tied to 0); 0=NONE (Always inactive)
0x564 UDMACH12BSEL access per field reset 0x50 — Output Selection for DMA Channel 12 REQ DMA_DONE for the corresponding DMA channel is available as interrupt on GPT1 as GPT1:RIS.DMABRIS
  fields as UDMACH9BSEL
0x568 UDMACH13SSEL reset 0x3 — Software should not rely on the value of a reserved. Writing any other value than the reset value may result in undefined behavior.
  [31:0] EV
    3=AON_PROG2 (AON programmable event 2. Event selected by AON_EVENT MCU event selector, AON_EVENT:EVTOMCUSEL.AON_PROG2_EV)
0x56C UDMACH13BSEL reset 0x3 — Output Selection for DMA Channel 13 REQ
  [6:0] EV — Read only selection value
    values as UDMACH13SSEL.EV
0x570 UDMACH14SSEL rw reset 0x1 — Software should not rely on the value of a reserved. Writing any other value than the reset value may result in undefined behavior.
  [31:0] EV
    values as CPUIRQSEL29.EV
0x574 UDMACH14BSEL access per field reset 0x1 — Output Selection for DMA Channel 14 REQ
  [6:0] EV rw — Read/write selection value Writing any other value than values defined by a ENUM may result in undefined behavior.
    121=ALWAYS_ACTIVE (Always asserted); 120=CPU_HALTED; 119=AON_RTC_UPD (RTC periodic event controlled by AON_RTC:CTL.RTC_UPD_EN); 118=AUX_DMABREQ (DMA burst request event from AUX, configured by AUX_EVCTL:DMACTL); 117=AUX_DMASREQ (DMA single request event from AUX, configured by AUX_EVCTL:DMACTL); 116=AUX_SW_DMABREQ (DMA sofware trigger from AUX, triggered by AUX_EVCTL:DMASWREQ.START); 115=AUX_ADC_IRQ (AUX ADC interrupt event, corresponds to AUX_EVCTL:EVTOMCUFLAGS.ADC_IRQ. Status flags are found here AUX_EVCTL:EVTOMCUFLAGS); 114=AUX_OBSMUX0 (Loopback of OBSMUX0 through AUX, corresponds to AUX_EVCTL:EVTOMCUFLAGS.OBSMUX0); 113=AUX_ADC_FIFO_ALMOST_FULL (AUX ADC FIFO watermark event, corresponds to AUX_EVCTL:EVTOMCUFLAGS.ADC_FIFO_ALMOST_FULL); 112=AUX_ADC_DONE (AUX ADC done, corresponds to AUX_EVCTL:EVTOMCUFLAGS.ADC_DONE); 111=AUX_SMPH_AUTOTAKE_DONE (Autotake event from AUX semaphore, configured by AUX_SMPH:AUTOTAKE); 110=AUX_TIMER1_EV (AUX timer 1 event, corresponds to AUX_EVCTL:EVTOMCUFLAGS.TIMER1_EV); 109=AUX_TIMER0_EV (AUX timer 0 event, corresponds to AUX_EVCTL:EVTOMCUFLAGS.TIMER0_EV); 108=AUX_TDC_DONE (AUX TDC measurement done event, corresponds to the flag AUX_EVCTL:EVTOMCUFLAGS.TDC_DONE and the AUX_TDC status AUX_TDC:STAT.DONE); 107=AUX_COMPB (AUX Compare B event, corresponds to AUX_EVCTL:EVTOMCUFLAGS.AUX_COMPB); 106=AUX_COMPA (AUX Compare A event, corresponds to AUX_EVCTL:EVTOMCUFLAGS.AUX_COMPA); 105=AUX_AON_WU_EV (AON wakeup event, corresponds flags are here AUX_EVCTL:EVTOMCUFLAGS.AON_WU_EV); 104=TRNG_IRQ (TRNG Interrupt event, controlled by TRNG:IRQEN.EN); {v}=SWEV{v-100} (Software event {v-100}, triggered by SWEV.SWEV{v-100}) (v=100..103); 99=WDT_NMI (Watchdog non maskable interrupt event, controlled by WDT:CTL.INTTYPE); 94=CRYPTO_DMA_DONE_IRQ (CRYPTO DMA input done event, the correspondingg flag is CRYPTO:IRQSTAT.DMA_IN_DONE. Controlled by CRYPTO:IRQEN.DMA_IN_DONE); 93=CRYPTO_RESULT_AVAIL_IRQ (CRYPTO result available interupt event, the corresponding flag is found here CRYPTO:IRQSTAT.RESULT_AVAIL. Controlled by CRYPTO:IRQSTAT.RESULT_AVAIL); 92=PORT_EVENT7 (Port capture event from IOC, configured by IOC:IOCFGn.PORT_ID. Events on ports configured with ENUM PORT_EVENT7 wil be routed here.); 91=PORT_EVENT6 (Port capture event from IOC, configured by IOC:IOCFGn.PORT_ID. Events on ports configured with ENUM PORT_EVENT6 wil be routed here.); 90=PORT_EVENT5 (Port capture event from IOC, configured by IOC:IOCFGn.PORT_ID. Events on ports configured with ENUM PORT_EVENT4 wil be routed here.); {v}=PORT_EVENT{v-85} (Port capture event from IOC, configured by IOC:IOCFGn.PORT_ID. Events on ports configured with ENUM PORT_EVENT{v-85} wil be routed here.) (v=85..89); 84=GPT3B_DMABREQ (GPT3B DMA trigger event. Configured by GPT3:DMAEV); 83=GPT3A_DMABREQ (GPT3A DMA trigger event. Configured by GPT3:DMAEV); 82=GPT2B_DMABREQ (GPT2B DMA trigger event. Configured by GPT2:DMAEV); 81=GPT2A_DMABREQ (GPT2A DMA trigger event. Configured by GPT2:DMAEV); 80=GPT1B_DMABREQ (GPT1B DMA trigger event. Configured by GPT1:DMAEV); 79=GPT1A_DMABREQ (GPT1A DMA trigger event. Configured by GPT1:DMAEV); 78=GPT0B_DMABREQ (GPT0B DMA trigger event. Configured by GPT0:DMAEV); 77=GPT0A_DMABREQ (GPT0A DMA trigger event. Configured by GPT0:DMAEV); 68=GPT3B_CMP (GPT3B compare event. Configured by GPT3:TBMR.TCACT); 67=GPT3A_CMP (GPT3A compare event. Configured by GPT3:TAMR.TCACT); 66=GPT2B_CMP (GPT2B compare event. Configured by GPT2:TBMR.TCACT); 65=GPT2A_CMP (GPT2A compare event. Configured by GPT2:TAMR.TCACT); 64=GPT1B_CMP (GPT1B compare event. Configured by GPT1:TBMR.TCACT); 63=GPT1A_CMP (GPT1A compare event. Configured by GPT1:TAMR.TCACT); 62=GPT0B_CMP (GPT0B compare event. Configured by GPT0:TBMR.TCACT); 61=GPT0A_CMP (GPT0A compare event. Configured by GPT0:TAMR.TCACT); 51=UART0_TX_DMASREQ (UART0 TX DMA single request, controlled by UART0:DMACTL.TXDMAE); 50=UART0_TX_DMABREQ (UART0 TX DMA burst request, controlled by UART0:DMACTL.TXDMAE); 49=UART0_RX_DMASREQ (UART0 RX DMA single request, controlled by UART0:DMACTL.RXDMAE); 48=UART0_RX_DMABREQ (UART0 RX DMA burst request, controlled by UART0:DMACTL.RXDMAE); 47=SSI1_TX_DMASREQ (SSI1 TX DMA single request, controlled by SSI0:DMACR.TXDMAE); 46=SSI1_TX_DMABREQ (SSI1 TX DMA burst request , controlled by SSI0:DMACR.TXDMAE); 45=SSI1_RX_DMASREQ (SSI1 RX DMA single request, controlled by SSI0:DMACR.RXDMAE); 44=SSI1_RX_DMABREQ (SSI1 RX DMA burst request , controlled by SSI0:DMACR.RXDMAE); 43=SSI0_TX_DMASREQ (SSI0 TX DMA single request, controlled by SSI0:DMACR.TXDMAE); 42=SSI0_TX_DMABREQ (SSI0 TX DMA burst request , controlled by SSI0:DMACR.TXDMAE); 41=SSI0_RX_DMASREQ (SSI0 RX DMA single request, controlled by SSI0:DMACR.RXDMAE); 40=SSI0_RX_DMABREQ (SSI0 RX DMA burst request , controlled by SSI0:DMACR.RXDMAE); 39=DMA_DONE_COMB (Combined DMA done, corresponding flags are here UDMA0:REQDONE); 38=DMA_ERR (DMA bus error, corresponds to UDMA0:ERROR.STATUS); 36=UART0_COMB (UART0 combined interrupt, interrupt flags are found here UART0:MIS); 35=SSI1_COMB (SSI1 combined interrupt, interrupt flags are found here SSI1:MIS); 34=SSI0_COMB (SSI0 combined interrupt, interrupt flags are found here SSI0:MIS); 30=RFC_CPE_1 (Combined Interrupt for CPE Generated events. Corresponding flags are here RFC_DBELL:RFCPEIFG. Only interrupts selected with CPE1 in RFC_DBELL:RFCPEIFG can trigger a RFC_CPE_1 event); 29=AUX_SWEV1 (AUX software event 1, triggered by AUX_EVCTL:SWEVSET.SWEV1, also available as AUX_EVENT2 AON wake up event. MCU domain wakeup control AON_EVENT:MCUWUSEL AUX domain wakeup control AON_EVENT:AUXWUSEL); 27=RFC_CPE_0 (Combined Interrupt for CPE Generated events. Corresponding flags are here RFC_DBELL:RFCPEIFG. Only interrupts selected with CPE0 in RFC_DBELL:RFCPEIFG can trigger a RFC_CPE_0 event); 26=RFC_HW_COMB (Combined RFC hardware interrupt, corresponding flag is here RFC_DBELL:RFHWIFG); 25=RFC_CMD_ACK (RFC Doorbell Command Acknowledgement Interrupt, equvialent to RFC_DBELL:RFACKIFG.ACKFLAG); 24=WDT_IRQ (Watchdog interrupt event, controlled by WDT:CTL.INTEN); 22=DMA_CH18_DONE (DMA done for software tiggered UDMA channel 18, see UDMA0:SOFTREQ); 21=FLASH (FLASH controller error event, the status flags are FLASH:FEDACSTAT.FSM_DONE and FLASH:FEDACSTAT.RVF_INT); 20=DMA_CH0_DONE (DMA done for software tiggered UDMA channel 0, see UDMA0:SOFTREQ); 19=GPT1B (GPT1B interrupt event, controlled by GPT1:TBMR); 18=GPT1A (GPT1A interrupt event, controlled by GPT1:TAMR); 17=GPT0B (GPT0B interrupt event, controlled by GPT0:TBMR); 16=GPT0A (GPT0A interrupt event, controlled by GPT0:TAMR); 15=GPT3B (GPT3B interrupt event, controlled by GPT3:TBMR); 14=GPT3A (GPT3A interrupt event, controlled by GPT3:TAMR); 13=GPT2B (GPT2B interrupt event, controlled by GPT2:TBMR); 12=GPT2A (GPT2A interrupt event, controlled by GPT2:TAMR); 11=AUX_COMB (AUX combined event, the corresponding flag register is here AUX_EVCTL:EVTOMCUFLAGS); 10=AON_AUX_SWEV0 (AUX Software event 0, AUX_EVCTL:SWEVSET.SWEV0); 9=I2C_IRQ (Interrupt event from I2C); 8=I2S_IRQ (Interrupt event from I2S); 7=AON_RTC_COMB (Event from AON_RTC, controlled by the AON_RTC:CTL.COMB_EV_MASK setting); 4=AON_GPIO_EDGE (Edge detect event from IOC. Configureded by the IOC:IOCFGn.EDGE_IRQ_EN and IOC:IOCFGn.EDGE_DET settings); 3=AON_PROG2 (AON programmable event 2. Event selected by AON_EVENT MCU event selector, AON_EVENT:EVTOMCUSEL.AON_PROG2_EV); 2=AON_PROG1 (AON programmable event 1. Event selected by AON_EVENT MCU event selector, AON_EVENT:EVTOMCUSEL.AON_PROG1_EV); 1=AON_PROG0 (AON programmable event 0. Event selected by AON_EVENT MCU event selector, AON_EVENT:EVTOMCUSEL.AON_PROG0_EV); 0=NONE (Always inactive)
0x578 UDMACH15SSEL reset 0x7 — Software should not rely on the value of a reserved. Writing any other value than the reset value may result in undefined behavior.
  [31:0] EV
    values as CPUIRQSEL4.EV
0x57C UDMACH15BSEL reset 0x7 — Output Selection for DMA Channel 15 REQ
  fields as CPUIRQSEL4
0x580 UDMACH16SSEL reset 0x2D — Output Selection for DMA Channel 16 SREQ
  [6:0] EV — Read only selection value
    45=SSI1_RX_DMASREQ (SSI1 RX DMA single request, controlled by SSI0:DMACR.RXDMAE)
0x584 UDMACH16BSEL reset 0x2C — Output Selection for DMA Channel 16 REQ
  [6:0] EV — Read only selection value
    44=SSI1_RX_DMABREQ (SSI1 RX DMA burst request , controlled by SSI0:DMACR.RXDMAE)
0x588 UDMACH17SSEL reset 0x2F — Output Selection for DMA Channel 17 SREQ
  [6:0] EV — Read only selection value
    47=SSI1_TX_DMASREQ (SSI1 TX DMA single request, controlled by SSI0:DMACR.TXDMAE)
0x58C UDMACH17BSEL reset 0x2E — Output Selection for DMA Channel 17 REQ
  [6:0] EV — Read only selection value
    46=SSI1_TX_DMABREQ (SSI1 TX DMA burst request , controlled by SSI0:DMACR.TXDMAE)
{0x500+8i} UDMACH{i}SSEL (i=18..20) — Software should not rely on the value of a reserved. Writing any other value than the reset value may result in undefined behavior.
  [31:0] EV
    0=NONE (Always inactive)
{0x504+8i} UDMACH{i}BSEL (i=18..20) — Software should not rely on the value of a reserved. Writing any other value than the reset value may result in undefined behavior.
  [31:0] EV
    0=NONE (Always inactive)
0x5A8 UDMACH21SSEL reset 0x64 — Output Selection for DMA Channel 21 SREQ
  fields as CPUIRQSEL27
0x5AC UDMACH21BSEL reset 0x64 — Output Selection for DMA Channel 21 REQ
  fields as CPUIRQSEL27
0x5B0 UDMACH22SSEL reset 0x65 — Output Selection for DMA Channel 22 SREQ
  [6:0] EV — Read only selection value
    101=SWEV1 (Software event 1, triggered by SWEV.SWEV1)
0x5B4 UDMACH22BSEL reset 0x65 — Output Selection for DMA Channel 22 REQ
  fields as UDMACH22SSEL
0x5B8 UDMACH23SSEL reset 0x66 — Output Selection for DMA Channel 23 SREQ
  [6:0] EV — Read only selection value
    102=SWEV2 (Software event 2, triggered by SWEV.SWEV2)
0x5BC UDMACH23BSEL reset 0x66 — Output Selection for DMA Channel 23 REQ
  fields as UDMACH23SSEL
0x5C0 UDMACH24SSEL reset 0x67 — Output Selection for DMA Channel 24 SREQ
  [6:0] EV — Read only selection value
    103=SWEV3 (Software event 3, triggered by SWEV.SWEV3)
0x5C4 UDMACH24BSEL reset 0x67 — Output Selection for DMA Channel 24 REQ
  fields as UDMACH24SSEL
{0x500+8i} UDMACH{i}SSEL (i=25..31) — Software should not rely on the value of a reserved. Writing any other value than the reset value may result in undefined behavior.
  [31:0] EV
    0=NONE (Always inactive)
{0x504+8i} UDMACH{i}BSEL (i=25..31) — Software should not rely on the value of a reserved. Writing any other value than the reset value may result in undefined behavior.
  [31:0] EV
    0=NONE (Always inactive)
0x600 GPT3ACAPTSEL access per field reset 0x5B — Output Selection for GPT3 0
  [6:0] EV rw — Read/write selection value Writing any other value than values defined by a ENUM may result in undefined behavior.
    121=ALWAYS_ACTIVE (Always asserted); 119=AON_RTC_UPD (RTC periodic event controlled by AON_RTC:CTL.RTC_UPD_EN); 115=AUX_ADC_IRQ (AUX ADC interrupt event, corresponds to AUX_EVCTL:EVTOMCUFLAGS.ADC_IRQ. Status flags are found here AUX_EVCTL:EVTOMCUFLAGS); 114=AUX_OBSMUX0 (Loopback of OBSMUX0 through AUX, corresponds to AUX_EVCTL:EVTOMCUFLAGS.OBSMUX0); 113=AUX_ADC_FIFO_ALMOST_FULL (AUX ADC FIFO watermark event, corresponds to AUX_EVCTL:EVTOMCUFLAGS.ADC_FIFO_ALMOST_FULL); 112=AUX_ADC_DONE (AUX ADC done, corresponds to AUX_EVCTL:EVTOMCUFLAGS.ADC_DONE); 111=AUX_SMPH_AUTOTAKE_DONE (Autotake event from AUX semaphore, configured by AUX_SMPH:AUTOTAKE); 110=AUX_TIMER1_EV (AUX timer 1 event, corresponds to AUX_EVCTL:EVTOMCUFLAGS.TIMER1_EV); 109=AUX_TIMER0_EV (AUX timer 0 event, corresponds to AUX_EVCTL:EVTOMCUFLAGS.TIMER0_EV); 108=AUX_TDC_DONE (AUX TDC measurement done event, corresponds to the flag AUX_EVCTL:EVTOMCUFLAGS.TDC_DONE and the AUX_TDC status AUX_TDC:STAT.DONE); 107=AUX_COMPB (AUX Compare B event, corresponds to AUX_EVCTL:EVTOMCUFLAGS.AUX_COMPB); 106=AUX_COMPA (AUX Compare A event, corresponds to AUX_EVCTL:EVTOMCUFLAGS.AUX_COMPA); 105=AUX_AON_WU_EV (AON wakeup event, corresponds flags are here AUX_EVCTL:EVTOMCUFLAGS.AON_WU_EV); 92=PORT_EVENT7 (Port capture event from IOC, configured by IOC:IOCFGn.PORT_ID. Events on ports configured with ENUM PORT_EVENT7 wil be routed here.); 91=PORT_EVENT6 (Port capture event from IOC, configured by IOC:IOCFGn.PORT_ID. Events on ports configured with ENUM PORT_EVENT6 wil be routed here.); 68=GPT3B_CMP (GPT3B compare event. Configured by GPT3:TBMR.TCACT); 67=GPT3A_CMP (GPT3A compare event. Configured by GPT3:TAMR.TCACT); 66=GPT2B_CMP (GPT2B compare event. Configured by GPT2:TBMR.TCACT); 65=GPT2A_CMP (GPT2A compare event. Configured by GPT2:TAMR.TCACT); 64=GPT1B_CMP (GPT1B compare event. Configured by GPT1:TBMR.TCACT); 63=GPT1A_CMP (GPT1A compare event. Configured by GPT1:TAMR.TCACT); 62=GPT0B_CMP (GPT0B compare event. Configured by GPT0:TBMR.TCACT); 61=GPT0A_CMP (GPT0A compare event. Configured by GPT0:TAMR.TCACT); 36=UART0_COMB (UART0 combined interrupt, interrupt flags are found here UART0:MIS); 35=SSI1_COMB (SSI1 combined interrupt, interrupt flags are found here SSI1:MIS); 34=SSI0_COMB (SSI0 combined interrupt, interrupt flags are found here SSI0:MIS); 30=RFC_CPE_1 (Combined Interrupt for CPE Generated events. Corresponding flags are here RFC_DBELL:RFCPEIFG. Only interrupts selected with CPE1 in RFC_DBELL:RFCPEIFG can trigger a RFC_CPE_1 event); 27=RFC_CPE_0 (Combined Interrupt for CPE Generated events. Corresponding flags are here RFC_DBELL:RFCPEIFG. Only interrupts selected with CPE0 in RFC_DBELL:RFCPEIFG can trigger a RFC_CPE_0 event); 26=RFC_HW_COMB (Combined RFC hardware interrupt, corresponding flag is here RFC_DBELL:RFHWIFG); 25=RFC_CMD_ACK (RFC Doorbell Command Acknowledgement Interrupt, equvialent to RFC_DBELL:RFACKIFG.ACKFLAG); 21=FLASH (FLASH controller error event, the status flags are FLASH:FEDACSTAT.FSM_DONE and FLASH:FEDACSTAT.RVF_INT); 11=AUX_COMB (AUX combined event, the corresponding flag register is here AUX_EVCTL:EVTOMCUFLAGS); 7=AON_RTC_COMB (Event from AON_RTC, controlled by the AON_RTC:CTL.COMB_EV_MASK setting); 4=AON_GPIO_EDGE (Edge detect event from IOC. Configureded by the IOC:IOCFGn.EDGE_IRQ_EN and IOC:IOCFGn.EDGE_DET settings); 0=NONE (Always inactive)
0x604 GPT3BCAPTSEL access per field reset 0x5C — Output Selection for GPT3 1
  fields as GPT3ACAPTSEL
0x700 AUXSEL0 access per field reset 0x10 — Output Selection for AUX Subscriber 0
  [6:0] EV rw — Read/write selection value Writing any other value than values defined by a ENUM may result in undefined behavior.
    121=ALWAYS_ACTIVE (Always asserted); 19=GPT1B (GPT1B interrupt event, controlled by GPT1:TBMR); 18=GPT1A (GPT1A interrupt event, controlled by GPT1:TAMR); 17=GPT0B (GPT0B interrupt event, controlled by GPT0:TBMR); 16=GPT0A (GPT0A interrupt event, controlled by GPT0:TAMR); 15=GPT3B (GPT3B interrupt event, controlled by GPT3:TBMR); 14=GPT3A (GPT3A interrupt event, controlled by GPT3:TAMR); 13=GPT2B (GPT2B interrupt event, controlled by GPT2:TBMR); 12=GPT2A (GPT2A interrupt event, controlled by GPT2:TAMR); 0=NONE (Always inactive)
0x800 CM3NMISEL0 reset 0x63 — Output Selection for NMI Subscriber 0
  [6:0] EV — Read only selection value
    99=WDT_NMI (Watchdog non maskable interrupt event, controlled by WDT:CTL.INTTYPE)
0x900 I2SSTMPSEL0 access per field reset 0x5F — Output Selection for I2S Subscriber 0
  [6:0] EV rw — Read/write selection value Writing any other value than values defined by a ENUM may result in undefined behavior.
    121=ALWAYS_ACTIVE (Always asserted); 0=NONE (Always inactive)
0xA00 FRZSEL0 access per field reset 0x78 — Output Selection for FRZ Subscriber The halted debug signal is passed to peripherals such as the General Purpose Timer, Sensor Controller with Digital and Analog Peripherals (AUX), Radio, and RTC. When the system CPU halts, the connected peripherals that have freeze enabled also halt. The programmable output can be set to static values of 0 or 1, and can also be set to pass the halted signal.
  [6:0] EV rw — Read/write selection value Writing any other value than values defined by a ENUM may result in undefined behavior.
    121=ALWAYS_ACTIVE (Always asserted); 120=CPU_HALTED; 0=NONE (Always inactive)
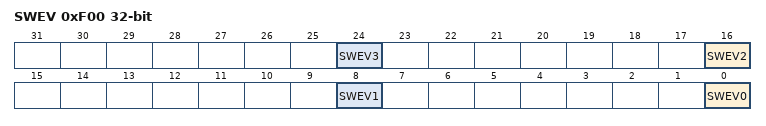
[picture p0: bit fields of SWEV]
0xF00 SWEV access per field — Set or Clear Software Events
  [8n] SWEV{n} rw (n=0..3) — Writing "1" to this bit when the value is "0" triggers the Software {n} event.
